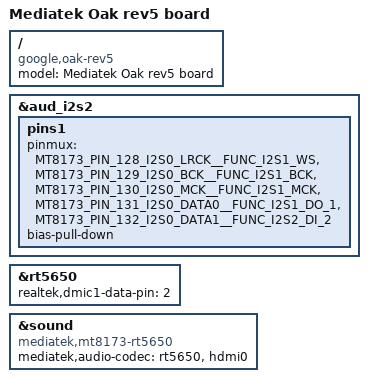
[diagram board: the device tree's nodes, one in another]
// SPDX-License-Identifier: GPL-2.0-only
/*
 * Copyright 2020 MediaTek Inc.
 */

/dts-v1/;
#include "mt8173-elm.dtsi"

/ {
	model = "Mediatek Oak rev5 board";
	compatible = "google,oak-rev5", "google,oak", "mediatek,mt8173";
};

&aud_i2s2 {
	pins1 {
		pinmux = <MT8173_PIN_128_I2S0_LRCK__FUNC_I2S1_WS>,
			 <MT8173_PIN_129_I2S0_BCK__FUNC_I2S1_BCK>,
			 <MT8173_PIN_130_I2S0_MCK__FUNC_I2S1_MCK>,
			 <MT8173_PIN_131_I2S0_DATA0__FUNC_I2S1_DO_1>,
			 <MT8173_PIN_132_I2S0_DATA1__FUNC_I2S2_DI_2>;
		bias-pull-down;
	};
};

&rt5650 {
	 realtek,dmic1-data-pin = <2>;
};

&sound {
	compatible = "mediatek,mt8173-rt5650";
	mediatek,audio-codec = <&rt5650 &hdmi0>;
};
